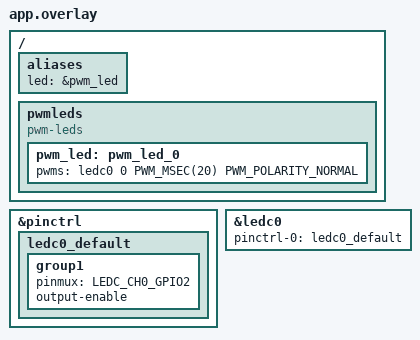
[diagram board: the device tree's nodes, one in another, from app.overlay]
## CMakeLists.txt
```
cmake_minimum_required(VERSION 3.20.0)

# Load Zephyr build environment
find_package(Zephyr REQUIRED HINTS $ENV{ZEPHYR_BASE})

project(zephyr_pwm_demo)

# Target executable source files
target_sources(app PRIVATE src/main.c)
```

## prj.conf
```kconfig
CONFIG_PWM=y
CONFIG_LOG=y
CONFIG_LOG_DEFAULT_LEVEL=3

CONFIG_SERIAL=y
CONFIG_CONSOLE=y
CONFIG_UART_CONSOLE=y

CONFIG_MULTITHREADING=y
CONFIG_SYS_CLOCK_TICKS_PER_SEC=1000
```

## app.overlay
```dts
#include <zephyr/dt-bindings/pwm/pwm.h>

/ {
    aliases {
        led = &pwm_led;
    };

    pwmleds {
        compatible = "pwm-leds";
        pwm_led: pwm_led_0 {
            /* Route to LEDC Channel 0, 20ms period, normal polarity */
            pwms = <&ledc0 0 PWM_MSEC(20) PWM_POLARITY_NORMAL>;
        };
    };
};

&pinctrl {
    ledc0_default: ledc0_default {
        group1 {
            pinmux = <LEDC_CH0_GPIO2>;
            output-enable;
        };
    };
};

&ledc0 {
    status = "okay";
    pinctrl-0 = <&ledc0_default>;
    pinctrl-names = "default";
    #pwm-cells = <3>;
};
```

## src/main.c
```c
#include <zephyr/kernel.h>
#include <zephyr/drivers/pwm.h>
#include <zephyr/logging/log.h>

#define PWM DT_ALIAS(led)
#if !DT_NODE_EXISTS(PWM)
#error "No PWM device found"
#endif


static const struct pwm_dt_spec pwm = PWM_DT_SPEC_GET(PWM);

#define STEP (pwm.period/20)

LOG_MODULE_REGISTER(pwm_demo, LOG_LEVEL_INF);

int main(void)
{
    LOG_INF("PWM Demo");

    int ret;
    uint32_t pulse_width=0;

    if (!pwm_is_ready_dt(&pwm)) {
        LOG_ERR("PWM controller device is not ready!");
        return -ENODEV;
    }
    
    while(1)
    {
        ret = pwm_set_pulse_dt(&pwm,pulse_width);
        if(ret < 0)
        {
            LOG_ERR("Failed to set pulse width");
            return ret;
        }
        pulse_width += STEP;

        if(pulse_width > pwm.period)
        {
            pulse_width = 0;
        }
        k_msleep(50);

    }
}
```
